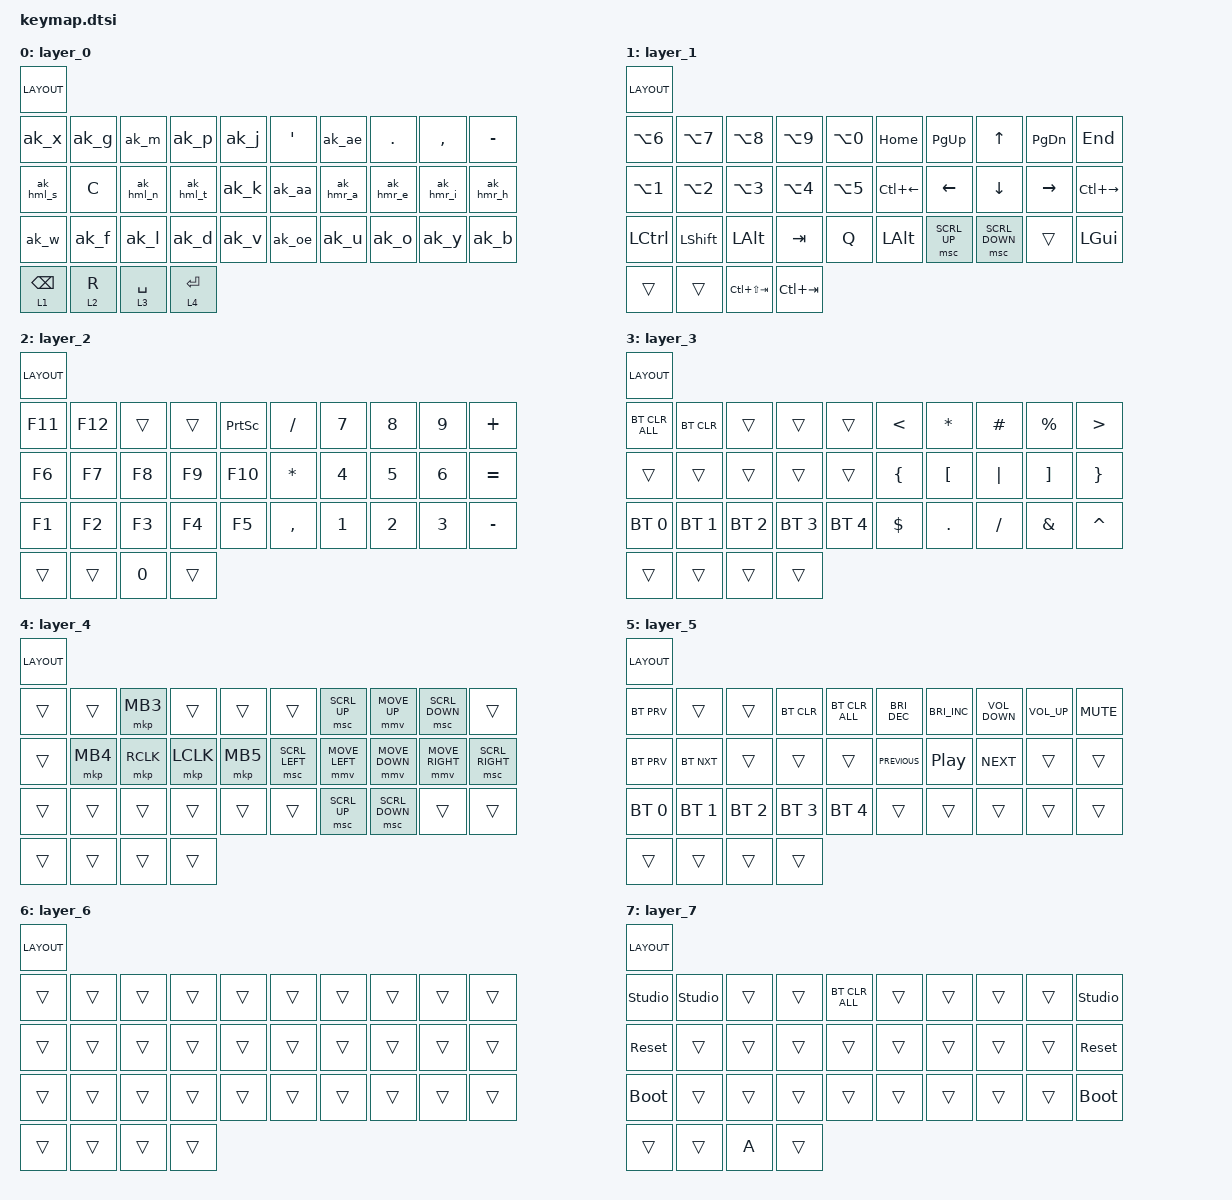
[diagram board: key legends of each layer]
// Shared by every board. The board file must define LAYOUT() and POS00..POS33
// before including this file.

#include <behaviors.dtsi>
#include <dt-bindings/zmk/bt.h>
#include <dt-bindings/zmk/keys.h>
#include <dt-bindings/zmk/pointing.h>

// Using Urob's timeless homerow mods
// Trying to make sure that sticky shift only shifts one key after being pressed.

&sk {
    release-after-ms = <1000>;
    quick-release;
};

// Faster mouse movements

#define ZMK_POINTING_DEFAULT_MOVE_VAL 1500  // default: 600
#define ZMK_POINTING_DEFAULT_SCRL_VAL 20    // default: 10

/ {
    behaviors {
        hml: home_row_mod_left {
            compatible = "zmk,behavior-hold-tap";
            #binding-cells = <2>;
            flavor = "balanced";
            require-prior-idle-ms = <150>;
            tapping-term-ms = <280>;
            quick-tap-ms = <175>;
            bindings = <&kp>, <&kp>;

            hold-trigger-key-positions = <POS00 POS01 POS02 POS03 POS04 POS10 POS11 POS12 POS13 POS14 POS20 POS21 POS22 POS23 POS24 POS30 POS31>; // List of keys on the right side of the keyboard
            hold-trigger-on-release;
        };

        hmr: home_row_mod_right {
            compatible = "zmk,behavior-hold-tap";
            #binding-cells = <2>;
            flavor = "balanced";
            require-prior-idle-ms = <150>;
            tapping-term-ms = <280>;
            quick-tap-ms = <175>;
            bindings = <&kp>, <&kp>;

            hold-trigger-key-positions = <POS05 POS06 POS07 POS08 POS09 POS15 POS16 POS17 POS18 POS19 POS25 POS26 POS27 POS28 POS29 POS32 POS33>; // List of keys on the left side of the keyboard
            hold-trigger-on-release;
        };

        // Comma Magic for homerow-mod S: tap after comma = capital S, hold = mod (unaffected)

        ak_hml_s: ak_hml_s {
            compatible = "zmk,behavior-adaptive-key";
            #binding-cells = <0>;
            bindings = <&hml LEFT_GUI S>;

            akt_comma_s {
                trigger-keys = <COMMA>;
                bindings = <&comma_cap_s>;
                max-prior-idle-ms = <500>;
            };
        };

        ak_hml_c: ak_hml_c {
            compatible = "zmk,behavior-adaptive-key";
            #binding-cells = <0>;
            bindings = <&hml LALT C>;

            akt_comma_c {
                trigger-keys = <COMMA>;
                bindings = <&comma_cap_c>;
                max-prior-idle-ms = <500>;
            };
        };

        ak_hml_n: ak_hml_n {
            compatible = "zmk,behavior-adaptive-key";
            #binding-cells = <0>;
            bindings = <&hml LEFT_SHIFT N>;

            akt_comma_n {
                trigger-keys = <COMMA>;
                bindings = <&comma_cap_n>;
                max-prior-idle-ms = <500>;
            };
        };

        ak_hml_t: ak_hml_t {
            compatible = "zmk,behavior-adaptive-key";
            #binding-cells = <0>;
            bindings = <&hml LEFT_CONTROL T>;

            akt_comma_t {
                trigger-keys = <COMMA>;
                bindings = <&comma_cap_t>;
                max-prior-idle-ms = <500>;
            };
        };

        // Comma Magic for homerow-mod A

        ak_hmr_a: ak_hmr_a {
            compatible = "zmk,behavior-adaptive-key";
            #binding-cells = <0>;
            bindings = <&hmr LEFT_CONTROL A>;

            akt_comma_a2 {
                trigger-keys = <COMMA>;
                bindings = <&comma_cap_a>;
                max-prior-idle-ms = <500>;
            };
        };

        ak_hmr_e: ak_hmr_e {
            compatible = "zmk,behavior-adaptive-key";
            #binding-cells = <0>;
            bindings = <&hmr RIGHT_SHIFT E>;

            akt_comma_e {
                trigger-keys = <COMMA>;
                bindings = <&comma_cap_e>;
                max-prior-idle-ms = <500>;
            };
        };

        ak_hmr_i: ak_hmr_i {
            compatible = "zmk,behavior-adaptive-key";
            #binding-cells = <0>;
            bindings = <&hmr LALT I>;

            akt_comma_i {
                trigger-keys = <COMMA>;
                bindings = <&comma_cap_i>;
                max-prior-idle-ms = <500>;
            };
        };

        ak_hmr_h: ak_hmr_h {
            compatible = "zmk,behavior-adaptive-key";
            #binding-cells = <0>;
            bindings = <&hmr LEFT_GUI H>;

            akt_comma_h {
                trigger-keys = <COMMA>;
                bindings = <&comma_cap_h>;
                max-prior-idle-ms = <500>;
            };
        };

        // // Trying to implement a sticky shift on tap, layer 1 on hold thing here.
        //
        // lt_sk: layer_tap_sticky_shift {
        //     compatible = "zmk,behavior-hold-tap";
        //     #binding-cells = <2>;
        //     flavor = "tap-preferred";
        //     tapping-term-ms = <150>;
        //     require-prior-idle-ms = <150>;
        //     bindings = <&mo>, <&sk>;
        // };
        // Layer-tap for R: hold = layer (param), tap = comma-aware R

        lt_r: layer_tap_r {
            compatible = "zmk,behavior-hold-tap";
            #binding-cells = <2>;
            flavor = "balanced";
            tapping-term-ms = <150>;
            require-prior-idle-ms = <150>;
            bindings = <&mo>, <&ak_r>;
        };

        // Comma Magic test: typing comma then G capitalizes it (deletes the comma)

        ak_g: ak_g {
            compatible = "zmk,behavior-adaptive-key";
            #binding-cells = <0>;
            bindings = <&kp G>;

            akt_comma_g {
                trigger-keys = <COMMA>;
                bindings = <&kp BSPC &kp LS(G)>;
                max-prior-idle-ms = <500>;
            };
        };

        ak_x: ak_x {
            compatible = "zmk,behavior-adaptive-key";
            #binding-cells = <0>;
            bindings = <&kp X>;

            akt_comma_x {
                trigger-keys = <COMMA>;
                bindings = <&kp BSPC &kp LS(X)>;
                max-prior-idle-ms = <500>;
            };
        };

        ak_q: ak_q {
            compatible = "zmk,behavior-adaptive-key";
            #binding-cells = <0>;
            bindings = <&kp Q>;

            akt_comma_q {
                trigger-keys = <COMMA>;
                bindings = <&kp BSPC &kp LS(Q)>;
                max-prior-idle-ms = <500>;
            };
        };

        ak_r: ak_r {
            compatible = "zmk,behavior-adaptive-key";
            #binding-cells = <0>;
            bindings = <&kp R>;

            akt_comma_r {
                trigger-keys = <COMMA>;
                bindings = <&kp BSPC &kp LS(R)>;
                max-prior-idle-ms = <500>;
            };
        };

        ak_m: ak_m {
            compatible = "zmk,behavior-adaptive-key";
            #binding-cells = <0>;
            bindings = <&kp M>;

            akt_comma_m {
                trigger-keys = <COMMA>;
                bindings = <&kp BSPC &kp LS(M)>;
                max-prior-idle-ms = <500>;
            };
        };

        ak_p: ak_p {
            compatible = "zmk,behavior-adaptive-key";
            #binding-cells = <0>;
            bindings = <&kp P>;

            akt_comma_p {
                trigger-keys = <COMMA>;
                bindings = <&kp BSPC &kp LS(P)>;
                max-prior-idle-ms = <500>;
            };
        };

        ak_j: ak_j {
            compatible = "zmk,behavior-adaptive-key";
            #binding-cells = <0>;
            bindings = <&kp J>;

            akt_comma_j {
                trigger-keys = <COMMA>;
                bindings = <&kp BSPC &kp LS(J)>;
                max-prior-idle-ms = <500>;
            };
        };

        ak_w: ak_w {
            compatible = "zmk,behavior-adaptive-key";
            #binding-cells = <0>;
            bindings = <&kp W>;

            akt_comma_w {
                trigger-keys = <COMMA>;
                bindings = <&kp BSPC &kp LS(W)>;
                max-prior-idle-ms = <500>;
            };
        };

        ak_f: ak_f {
            compatible = "zmk,behavior-adaptive-key";
            #binding-cells = <0>;
            bindings = <&kp F>;

            akt_comma_f {
                trigger-keys = <COMMA>;
                bindings = <&kp BSPC &kp LS(F)>;
                max-prior-idle-ms = <500>;
            };
        };

        ak_l: ak_l {
            compatible = "zmk,behavior-adaptive-key";
            #binding-cells = <0>;
            bindings = <&kp L>;

            akt_comma_l {
                trigger-keys = <COMMA>;
                bindings = <&kp BSPC &kp LS(L)>;
                max-prior-idle-ms = <500>;
            };
        };

        ak_d: ak_d {
            compatible = "zmk,behavior-adaptive-key";
            #binding-cells = <0>;
            bindings = <&kp D>;

            akt_comma_d {
                trigger-keys = <COMMA>;
                bindings = <&kp BSPC &kp LS(D)>;
                max-prior-idle-ms = <500>;
            };
        };

        ak_v: ak_v {
            compatible = "zmk,behavior-adaptive-key";
            #binding-cells = <0>;
            bindings = <&kp V>;

            akt_comma_v {
                trigger-keys = <COMMA>;
                bindings = <&kp BSPC &kp LS(V)>;
                max-prior-idle-ms = <500>;
            };
        };

        ak_u: ak_u {
            compatible = "zmk,behavior-adaptive-key";
            #binding-cells = <0>;
            bindings = <&kp U>;

            akt_comma_u {
                trigger-keys = <COMMA>;
                bindings = <&kp BSPC &kp LS(U)>;
                max-prior-idle-ms = <500>;
            };
        };

        ak_o: ak_o {
            compatible = "zmk,behavior-adaptive-key";
            #binding-cells = <0>;
            bindings = <&kp O>;

            akt_comma_o {
                trigger-keys = <COMMA>;
                bindings = <&kp BSPC &kp LS(O)>;
                max-prior-idle-ms = <500>;
            };
        };

        ak_y: ak_y {
            compatible = "zmk,behavior-adaptive-key";
            #binding-cells = <0>;
            bindings = <&kp Y>;

            akt_comma_y {
                trigger-keys = <COMMA>;
                bindings = <&kp BSPC &kp LS(Y)>;
                max-prior-idle-ms = <500>;
            };
        };

        ak_b: ak_b {
            compatible = "zmk,behavior-adaptive-key";
            #binding-cells = <0>;
            bindings = <&kp B>;

            akt_comma_b {
                trigger-keys = <COMMA>;
                bindings = <&kp BSPC &kp LS(B)>;
                max-prior-idle-ms = <500>;
            };
        };

        ak_k: ak_k {
            compatible = "zmk,behavior-adaptive-key";
            #binding-cells = <0>;
            bindings = <&kp K>;

            akt_comma_k {
                trigger-keys = <COMMA>;
                bindings = <&kp BSPC &kp LS(K)>;
                max-prior-idle-ms = <500>;
            };
        };

        // Comma Magic for umlaut macros: comma + umlaut produces the capitalized umlaut

        ak_ae: ak_ae {
            compatible = "zmk,behavior-adaptive-key";
            #binding-cells = <0>;
            bindings = <&ae_umlaut>;

            akt_comma_ae {
                trigger-keys = <COMMA>;
                bindings = <&kp BSPC &kp RA(LS(A))>;
                max-prior-idle-ms = <500>;
            };
        };

        ak_aa: ak_aa {
            compatible = "zmk,behavior-adaptive-key";
            #binding-cells = <0>;
            bindings = <&aa_umlaut>;

            akt_comma_aa {
                trigger-keys = <COMMA>;
                bindings = <&kp BSPC &kp RA(LS(W))>;
                max-prior-idle-ms = <500>;
            };
        };

        ak_oe: ak_oe {
            compatible = "zmk,behavior-adaptive-key";
            #binding-cells = <0>;
            bindings = <&oe_umlaut>;

            akt_comma_oe {
                trigger-keys = <COMMA>;
                bindings = <&kp BSPC &kp RA(LS(O))>;
                max-prior-idle-ms = <500>;
            };
        };
    };

    // Maybe add require-idle-ms 150 for horizontal combos and change timeout-ms to 30 for vertical and idle to 50 as per urob

    combos {
        compatible = "zmk,combos";

        //    timeout-ms = <20>;

        m_enter {
            bindings = <&kp ENTER>;
            key-positions = <POS16 POS17 POS18>;
            timeout-ms = <20>;
            require-prior-idle-ms = <150>;
        };

        th {
            bindings = <&th>;
            key-positions = <POS12 POS13>;
            timeout-ms = <20>;
        };

        left_par {
            bindings = <&kp LEFT_PARENTHESIS>;
            key-positions = <POS16 POS17>;
            timeout-ms = <20>;
            require-prior-idle-ms = <150>;
        };

        right_par {
            bindings = <&kp RIGHT_PARENTHESIS>;
            key-positions = <POS17 POS18>;
            timeout-ms = <20>;
            require-prior-idle-ms = <150>;
        };

        // equals {
        //     bindings = <&kp EQUAL>;
        //     key-positions = <POS18 POS19>;
        //     timeout-ms = <20>;
        // };

        colon {
            bindings = <&kp COLON>;
            key-positions = <POS16 POS18>;
            timeout-ms = <20>;
            require-prior-idle-ms = <150>;
        };

        curvy {
            bindings = <&kp TILDE>;
            key-positions = <POS25 POS29>;
            timeout-ms = <20>;
            require-prior-idle-ms = <150>;
        };

        underscore {
            bindings = <&kp UNDER>;
            key-positions = <POS28 POS26>;
            timeout-ms = <20>;
            require-prior-idle-ms = <150>;
        };

        snabela {
            bindings = <&kp AT>;
            key-positions = <POS05 POS06>;
            timeout-ms = <20>;
            require-prior-idle-ms = <150>;
        };

        tab {
            bindings = <&kp TAB>;
            key-positions = <POS00 POS01>;
            timeout-ms = <20>;
            require-prior-idle-ms = <150>;
        };

        Stab {
            bindings = <&kp LS(TAB)>;
            key-positions = <POS00 POS01 POS02>;
            timeout-ms = <20>;
            require-prior-idle-ms = <150>;
        };

        space {
            bindings = <&kp SPACE>;
            key-positions = <POS13 POS14>;
            timeout-ms = <20>;
            require-prior-idle-ms = <150>;
        };

        escape {
            bindings = <&kp ESCAPE>;
            key-positions = <POS10 POS13>;
            timeout-ms = <20>;
            require-prior-idle-ms = <150>;
        };

        zed {
            bindings = <&kp Z>;
            key-positions = <POS11 POS13>;
            timeout-ms = <20>;
            require-prior-idle-ms = <150>;
        };

        excl {
            bindings = <&kp EXCLAMATION>;
            key-positions = <POS06 POS07>;
            timeout-ms = <20>;
        };

        doubleq {
            bindings = <&kp DOUBLE_QUOTES>;
            key-positions = <POS06 POS08>;
            timeout-ms = <20>;
        };

        question {
            bindings = <&kp QUESTION>;
            key-positions = <POS07 POS08>;
            timeout-ms = <20>;
        };

        Backspace {
            bindings = <&kp BACKSPACE>;
            key-positions = <POS15 POS16>;
            timeout-ms = <20>;
        };

        ion {
            bindings = <&ion>;
            key-positions = <POS06 POS07 POS08>;
            timeout-ms = <20>;
        };

        ing {
            bindings = <&ing>;
            key-positions = <POS26 POS27 POS28>;
            timeout-ms = <20>;
        };

        gh {
            bindings = <&gh>;
            key-positions = <POS01 POS02>;
            timeout-ms = <20>;
        };

        wh {
            bindings = <&wh>;
            key-positions = <POS20 POS21>;
            timeout-ms = <20>;
        };

        sh {
            bindings = <&sh>;
            key-positions = <POS10 POS11>;
            timeout-ms = <20>;
        };

        ch {
            bindings = <&ch>;
            key-positions = <POS11 POS12>;
            timeout-ms = <20>;
        };

        ph {
            bindings = <&ph>;
            key-positions = <POS21 POS23>;
            timeout-ms = <20>;
        };

        copy {
            bindings = <&kp LC(C)>;
            key-positions = <POS21 POS22>;
            timeout-ms = <20>;
            require-prior-idle-ms = <150>;
        };

        paste {
            bindings = <&kp LC(V)>;
            key-positions = <POS22 POS23>;
            timeout-ms = <20>;
            require-prior-idle-ms = <150>;
        };

        sall {
            bindings = <&kp LC(A)>;
            key-positions = <POS20 POS23>;
            timeout-ms = <20>;
            require-prior-idle-ms = <150>;
        };

        undo {
            bindings = <&kp LC(Z)>;
            key-positions = <POS20 POS21 POS22>;
            timeout-ms = <20>;
            require-prior-idle-ms = <150>;
        };

        redo {
            bindings = <&kp LC(LS(Z))>;
            key-positions = <POS20 POS21 POS22 POS23>;
            timeout-ms = <20>;
            require-prior-idle-ms = <150>;
        };

        quit {
            bindings = <&kp LC(Q)>;
            key-positions = <POS04 POS14>;
            timeout-ms = <30>;
            require-prior-idle-ms = <50>;
        };

        new {
            bindings = <&kp LC(N)>;
            key-positions = <POS14 POS24>;
            timeout-ms = <20>;
            require-prior-idle-ms = <150>;
        };

        close {
            bindings = <&kp LC(W)>;
            key-positions = <POS05 POS15>;
            timeout-ms = <30>;
            require-prior-idle-ms = <50>;
        };

        open {
            bindings = <&kp LC(O)>;
            key-positions = <POS05 POS25>;
            timeout-ms = <20>;
            require-prior-idle-ms = <150>;
        };

        selword {
            bindings = <&selword>;
            key-positions = <POS20 POS24>;
            timeout-ms = <20>;
            require-prior-idle-ms = <150>;
        };

        findsel {
            bindings = <&findsel>;
            key-positions = <POS10 POS14>;
            timeout-ms = <20>;
            require-prior-idle-ms = <150>;
        };

        slash {
            bindings = <&kp SLASH>;
            key-positions = <POS01 POS02 POS03>;
            timeout-ms = <20>;
        };

        altslash {
            bindings = <&kp SLASH>;
            key-positions = <POS17 POS27>;
            timeout-ms = <30>;
            require-prior-idle-ms = <50>;
        };

        pipe {
            bindings = <&kp PIPE>;
            key-positions = <POS18 POS28>;
            timeout-ms = <30>;
            require-prior-idle-ms = <50>;
        };

        plus {
            bindings = <&kp PLUS>;
            key-positions = <POS06 POS16>;
            timeout-ms = <30>;
            require-prior-idle-ms = <50>;
        };

        minus {
            bindings = <&kp MINUS>;
            key-positions = <POS16 POS26>;
            timeout-ms = <30>;
            require-prior-idle-ms = <50>;
        };

        asterix {
            bindings = <&kp ASTRK>;
            key-positions = <POS07 POS17>;
            timeout-ms = <30>;
            require-prior-idle-ms = <50>;
        };

        andthen {
            bindings = <&kp AMPS>;
            key-positions = <POS08 POS18>;
            timeout-ms = <30>;
            require-prior-idle-ms = <50>;
        };

        lbracket {
            bindings = <&kp LEFT_BRACKET>;
            key-positions = <POS26 POS27>;
            timeout-ms = <20>;
            require-prior-idle-ms = <150>;
        };

        rbracket {
            bindings = <&kp RIGHT_BRACKET>;
            key-positions = <POS27 POS28>;
            timeout-ms = <20>;
            require-prior-idle-ms = <150>;
        };

        q {
            bindings = <&ak_q>;
            key-positions = <POS09 POS19>;
            timeout-ms = <30>;
            require-prior-idle-ms = <50>;
        };

        del {
            bindings = <&kp DELETE>;
            key-positions = <POS08 POS09>;
            timeout-ms = <20>;
            require-prior-idle-ms = <150>;
        };

        hash {
            bindings = <&kp HASH>;
            key-positions = <POS02 POS12>;
            timeout-ms = <30>;
            require-prior-idle-ms = <50>;
        };

        dollar {
            bindings = <&kp DOLLAR>;
            key-positions = <POS03 POS13>;
            timeout-ms = <30>;
            require-prior-idle-ms = <50>;
        };

        equality {
            bindings = <&kp EQUAL>;
            key-positions = <POS13 POS23>;
            timeout-ms = <30>;
            require-prior-idle-ms = <50>;
        };

        porciento {
            bindings = <&kp PERCENT>;
            key-positions = <POS00 POS10>;
            timeout-ms = <30>;
            require-prior-idle-ms = <50>;
        };

        grave {
            bindings = <&kp GRAVE>;
            key-positions = <POS10 POS20>;
            timeout-ms = <30>;
            require-prior-idle-ms = <50>;
        };

        backslash {
            bindings = <&kp BACKSLASH>;
            key-positions = <POS12 POS22>;
            timeout-ms = <30>;
            require-prior-idle-ms = <50>;
        };

        hd_enter {
            bindings = <&kp ENTER>;
            key-positions = <POS23 POS24>;
            timeout-ms = <20>;
            require-prior-idle-ms = <150>;
        };

        que {
            bindings = <&qu>;
            key-positions = <POS01 POS03>;
            timeout-ms = <20>;
        };

        sch {
            bindings = <&sch>;
            key-positions = <POS10 POS11 POS12>;
            timeout-ms = <20>;
        };

        tch {
            bindings = <&tch>;
            key-positions = <POS10 POS11 POS13>;
            timeout-ms = <20>;
        };

        Ill {
            bindings = <&Ill>;
            key-positions = <POS18 POS22>;
            timeout-ms = <30>;
        };

        Ive {
            bindings = <&Ive>;
            key-positions = <POS18 POS24>;
            timeout-ms = <30>;
        };

        Id {
            bindings = <&Id>;
            key-positions = <POS18 POS23>;
            timeout-ms = <30>;
        };

        Im {
            bindings = <&Im>;
            key-positions = <POS02 POS18>;
            timeout-ms = <30>;
        };

        Ime {
            bindings = <&kp LS(I)>;
            key-positions = <POS18 POS19>;
            timeout-ms = <20>;
            require-prior-idle-ms = <150>;
        };

        youll {
            bindings = <&youll>;
            key-positions = <POS22 POS28>;
            timeout-ms = <30>;
        };

        youve {
            bindings = <&youve>;
            key-positions = <POS24 POS28>;
            timeout-ms = <30>;
        };

        youd {
            bindings = <&youd>;
            key-positions = <POS23 POS28>;
            timeout-ms = <30>;
        };

        your {
            bindings = <&your>;
            key-positions = <POS28 POS30>;
            timeout-ms = <30>;
        };
    };

    // Maybe add timing to digraph macros - tap-ms = 10 (is the value that HD creator uses.)

    macros {
        comma_cap_s: comma_cap_s {
            compatible = "zmk,behavior-macro";
            #binding-cells = <0>;
            bindings = <&kp BSPC &kp LS(S)>;
            label = "COMMA_CAP_S";
        };

        comma_cap_c: comma_cap_c {
            compatible = "zmk,behavior-macro";
            #binding-cells = <0>;
            bindings = <&kp BSPC &kp LS(C)>;
            label = "COMMA_CAP_C";
        };

        comma_cap_n: comma_cap_n {
            compatible = "zmk,behavior-macro";
            #binding-cells = <0>;
            bindings = <&kp BSPC &kp LS(N)>;
            label = "COMMA_CAP_N";
        };

        comma_cap_t: comma_cap_t {
            compatible = "zmk,behavior-macro";
            #binding-cells = <0>;
            bindings = <&kp BSPC &kp LS(T)>;
            label = "COMMA_CAP_T";
        };

        comma_cap_a: comma_cap_a {
            compatible = "zmk,behavior-macro";
            #binding-cells = <0>;
            bindings = <&kp BSPC &kp LS(A)>;
            label = "COMMA_CAP_A";
        };

        comma_cap_e: comma_cap_e {
            compatible = "zmk,behavior-macro";
            #binding-cells = <0>;
            bindings = <&kp BSPC &kp LS(E)>;
            label = "COMMA_CAP_E";
        };

        comma_cap_i: comma_cap_i {
            compatible = "zmk,behavior-macro";
            #binding-cells = <0>;
            bindings = <&kp BSPC &kp LS(I)>;
            label = "COMMA_CAP_I";
        };

        comma_cap_h: comma_cap_h {
            compatible = "zmk,behavior-macro";
            #binding-cells = <0>;
            bindings = <&kp BSPC &kp LS(H)>;
            label = "COMMA_CAP_H";
        };

        ae_umlaut: ae_umlaut {
            compatible = "zmk,behavior-macro";
            #binding-cells = <0>;
            bindings = <&kp RA(A)>;
            label = "AE_UMLAUT";
        };

        aa_umlaut: aa_umlaut {
            compatible = "zmk,behavior-macro";
            #binding-cells = <0>;
            bindings = <&kp RA(W)>;
            label = "AA_UMLAUT";
        };

        oe_umlaut: oe_umlaut {
            compatible = "zmk,behavior-macro";
            #binding-cells = <0>;
            bindings = <&kp RA(O)>;
            label = "OE_UMLAUT";
        };

        // Plain adaptive-key for T (no mod), used only as the first step inside digraph macros

        ak_t: ak_t {
            compatible = "zmk,behavior-adaptive-key";
            #binding-cells = <0>;
            bindings = <&kp T>;

            akt_t_comma {
                trigger-keys = <COMMA>;
                bindings = <&kp BSPC &kp LS(T)>;
                max-prior-idle-ms = <500>;
                strict-modifiers;
            };
        };

        ak_c: ak_c {
            compatible = "zmk,behavior-adaptive-key";
            #binding-cells = <0>;
            bindings = <&kp C>;

            akt_c_comma {
                trigger-keys = <COMMA>;
                bindings = <&kp BSPC &kp LS(C)>;
                max-prior-idle-ms = <500>;
                strict-modifiers;
            };
        };

        ak_s: ak_s {
            compatible = "zmk,behavior-adaptive-key";
            #binding-cells = <0>;
            bindings = <&kp S>;

            akt_s_comma {
                trigger-keys = <COMMA>;
                bindings = <&kp BSPC &kp LS(S)>;
                max-prior-idle-ms = <500>;
                strict-modifiers;
            };
        };

        ak_i: ak_i {
            compatible = "zmk,behavior-adaptive-key";
            #binding-cells = <0>;
            bindings = <&kp I>;

            akt_i_comma {
                trigger-keys = <COMMA>;
                bindings = <&kp BSPC &kp LS(I)>;
                max-prior-idle-ms = <500>;
                strict-modifiers;
            };
        };

        ak_g2: ak_g2 {
            compatible = "zmk,behavior-adaptive-key";
            #binding-cells = <0>;
            bindings = <&kp G>;

            akt_g2_comma {
                trigger-keys = <COMMA>;
                bindings = <&kp BSPC &kp LS(G)>;
                max-prior-idle-ms = <500>;
                strict-modifiers;
            };
        };

        ak_p2: ak_p2 {
            compatible = "zmk,behavior-adaptive-key";
            #binding-cells = <0>;
            bindings = <&kp P>;

            akt_p2_comma {
                trigger-keys = <COMMA>;
                bindings = <&kp BSPC &kp LS(P)>;
                max-prior-idle-ms = <500>;
                strict-modifiers;
            };
        };

        th: th {
            compatible = "zmk,behavior-macro";
            #binding-cells = <0>;
            tap-ms = <10>;
            bindings =
                <&ak_t>,
                <&macro_release>,
                <&kp LSHFT>,
                <&macro_release>,
                <&kp RSHFT>,
                <&macro_tap>,
                <&kp H>;

            label = "TH";
        };

        ch: ch {
            compatible = "zmk,behavior-macro";
            #binding-cells = <0>;
            tap-ms = <10>;
            bindings =
                <&ak_c>,
                <&macro_release>,
                <&kp LSHFT>,
                <&macro_release>,
                <&kp RSHFT>,
                <&macro_tap>,
                <&kp H>;

            label = "CH";
        };

        sch: sch {
            compatible = "zmk,behavior-macro";
            #binding-cells = <0>;
            tap-ms = <10>;
            bindings =
                <&ak_s>,
                <&macro_release>,
                <&kp LSHFT>,
                <&macro_release>,
                <&kp RSHFT>,
                <&macro_tap>,
                <&kp C &kp H>;

            label = "SCH";
        };

        tch: tch {
            compatible = "zmk,behavior-macro";
            #binding-cells = <0>;
            tap-ms = <10>;
            bindings =
                <&ak_t>,
                <&macro_release>,
                <&kp LSHFT>,
                <&macro_release>,
                <&kp RSHFT>,
                <&macro_tap>,
                <&kp C &kp H>;

            label = "TCH";
        };

        qu: qu {
            compatible = "zmk,behavior-macro";
            #binding-cells = <0>;
            tap-ms = <10>;
            bindings =
                <&kp Q>,
                <&macro_release>,
                <&kp LSHFT>,
                <&macro_release>,
                <&kp RSHFT>,
                <&macro_tap>,
                <&kp U>;

            label = "QU";
        };

        wh: wh {
            compatible = "zmk,behavior-macro";
            #binding-cells = <0>;
            tap-ms = <10>;
            bindings =
                <&ak_w>,
                <&macro_release>,
                <&kp LSHFT>,
                <&macro_release>,
                <&kp RSHFT>,
                <&macro_tap>,
                <&kp H>;

            label = "WH";
        };

        sh: sh {
            compatible = "zmk,behavior-macro";
            #binding-cells = <0>;
            tap-ms = <10>;
            bindings =
                <&ak_s>,
                <&macro_release>,
                <&kp LSHFT>,
                <&macro_release>,
                <&kp RSHFT>,
                <&macro_tap>,
                <&kp H>;

            label = "SH";
        };

        ing: ing {
            compatible = "zmk,behavior-macro";
            #binding-cells = <0>;
            tap-ms = <10>;
            bindings =
                <&kp I>,
                <&macro_release>,
                <&kp LSHFT>,
                <&macro_release>,
                <&kp RSHFT>,
                <&macro_tap>,
                <&kp N &kp G>;

            label = "ING";
        };

        ion: ion {
            compatible = "zmk,behavior-macro";
            #binding-cells = <0>;
            tap-ms = <10>;
            bindings = <&kp I &kp O &kp N>;
            label = "ION";
        };

        gh: gh {
            compatible = "zmk,behavior-macro";
            #binding-cells = <0>;
            tap-ms = <10>;
            bindings =
                <&ak_g2>,
                <&macro_release>,
                <&kp LSHFT>,
                <&macro_release>,
                <&kp RSHFT>,
                <&macro_tap>,
                <&kp H>;

            label = "GH";
        };

        ph: ph {
            compatible = "zmk,behavior-macro";
            #binding-cells = <0>;
            tap-ms = <10>;
            bindings =
                <&ak_p2>,
                <&macro_release>,
                <&kp LSHFT>,
                <&macro_release>,
                <&kp RSHFT>,
                <&macro_tap>,
                <&kp H>;

            label = "PH";
        };

        findsel: findsel {
            compatible = "zmk,behavior-macro";
            #binding-cells = <0>;
            bindings =
                <&macro_tap>,
                <&kp LC(C)>,
                <&macro_tap>,
                <&kp LC(F)>,
                <&macro_tap>,
                <&kp LC(V)>,
                <&macro_tap>,
                <&kp RETURN>,
                <&macro_tap>,
                <&kp LC(G)>;

            label = "FINDSEL";
        };

        selword: selword {
            compatible = "zmk,behavior-macro";
            #binding-cells = <0>;
            bindings =
                <&macro_tap>,
                <&kp LC(LEFT)>,
                <&macro_tap>,
                <&kp LS(LC(RIGHT))>;

            label = "SELWORD";
        };

        your: your {
            compatible = "zmk,behavior-macro";
            #binding-cells = <0>;
            bindings =
                <&kp Y>,
                <&macro_release>,
                <&kp LSHFT>,
                <&macro_release>,
                <&kp RSHFT>,
                <&macro_tap>,
                <&kp O &kp U &kp R>;

            label = "YOUR";
        };

        Ill: Ill {
            compatible = "zmk,behavior-macro";
            #binding-cells = <0>;
            bindings = <&kp LS(I) &kp SQT &kp L &kp L &kp SPACE>;
            label = "ILL";
        };

        Id: Id {
            compatible = "zmk,behavior-macro";
            #binding-cells = <0>;
            bindings = <&kp LS(I) &kp SQT &kp D &kp SPACE>;
            label = "ID";
        };

        Im: Im {
            compatible = "zmk,behavior-macro";
            #binding-cells = <0>;
            bindings = <&kp LS(I) &kp SQT &kp M &kp SPACE>;
            label = "IM";
        };

        Ive: Ive {
            compatible = "zmk,behavior-macro";
            #binding-cells = <0>;
            bindings = <&kp LS(I) &kp SQT &kp V &kp E &kp SPACE>;
            label = "IVE";
        };

        youve: youve {
            compatible = "zmk,behavior-macro";
            #binding-cells = <0>;
            bindings =
                <&kp Y>,
                <&macro_release>,
                <&kp LSHFT>,
                <&macro_release>,
                <&kp RSHFT>,
                <&macro_tap>,
                <&kp O &kp U &kp APOSTROPHE &kp V &kp E &kp SPACE>;

            label = "YOUVE";
        };

        youre: youre {
            compatible = "zmk,behavior-macro";
            #binding-cells = <0>;
            bindings =
                <&kp Y>,
                <&macro_release>,
                <&kp LSHFT>,
                <&macro_release>,
                <&kp RSHFT>,
                <&macro_tap>,
                <&kp O &kp U &kp APOSTROPHE &kp R &kp E &kp SPACE>;

            label = "YOURE";
        };

        youd: youd {
            compatible = "zmk,behavior-macro";
            #binding-cells = <0>;
            bindings =
                <&kp Y>,
                <&macro_release>,
                <&kp LSHFT>,
                <&macro_release>,
                <&kp RSHFT>,
                <&macro_tap>,
                <&kp O &kp U &kp APOSTROPHE &kp D &kp SPACE>;

            label = "YOUD";
        };

        youll: youll {
            compatible = "zmk,behavior-macro";
            #binding-cells = <0>;
            bindings =
                <&kp Y>,
                <&macro_release>,
                <&kp LSHFT>,
                <&macro_release>,
                <&kp RSHFT>,
                <&macro_tap>,
                <&kp O &kp U &kp APOSTROPHE &kp L &kp L &kp SPACE>;

            label = "YOULL";
        };
    };

    keymap {
        compatible = "zmk,keymap";

        layer_0 {
            bindings = <
  LAYOUT(
    &ak_x,           &ak_g,           &ak_m,           &ak_p,           &ak_j,           &kp APOS,        &ak_ae,          &kp DOT,         &kp COMMA,       &kp MINUS,
    &ak_hml_s,       &kp C,       &ak_hml_n,       &ak_hml_t,       &ak_k,           &ak_aa,          &ak_hmr_a,       &ak_hmr_e,       &ak_hmr_i,       &ak_hmr_h,
    &ak_w,           &ak_f,           &ak_l,           &ak_d,           &ak_v,           &ak_oe,          &ak_u,           &ak_o,           &ak_y,           &ak_b,
    &lt 1 BACKSPACE, &lt_r 2 R,       &lt 3 SPACE,     &lt 4 ENTER
  )
    >;
        };

        layer_1 {
            bindings = <
  LAYOUT(
    &kp LA(NUMBER_6),    &kp LA(NUMBER_7),    &kp LA(N8),          &kp LA(N9),          &kp LA(N0),          &kp HOME,            &kp PAGE_UP,         &kp UP_ARROW,        &kp PAGE_DOWN,       &kp END,
    &kp LA(NUMBER_1),    &kp LA(NUMBER_2),    &kp LA(NUMBER_3),    &kp LA(NUMBER_4),    &kp LA(NUMBER_5),    &kp LC(LEFT_ARROW),  &kp LEFT_ARROW,      &kp DOWN_ARROW,      &kp RIGHT,           &kp LC(RIGHT_ARROW),
    &kp LEFT_CONTROL,    &kp LEFT_SHIFT,      &kp LEFT_ALT,        &kp TAB,             &kp Q,               &kp LEFT_ALT,        &msc SCRL_UP,        &msc SCRL_DOWN,      &trans,              &kp LEFT_GUI,
    &trans,              &trans,              &kp LC(LS(TAB)),     &kp LC(TAB)
  )
    >;
        };

        layer_2 {
            bindings = <
  LAYOUT(
    &kp F11,         &kp F12,         &trans,          &trans,          &kp PRINTSCREEN, &kp SLASH,       &kp N7,          &kp N8,          &kp N9,          &kp PLUS,
    &kp F6,          &kp F7,          &kp F8,          &kp F9,          &kp F10,         &kp ASTRK,       &kp NUMBER_4,    &kp N5,          &kp NUMBER_6,    &kp EQUAL,
    &kp F1,          &kp F2,          &kp F3,          &kp F4,          &kp F5,          &kp COMMA,       &kp NUMBER_1,    &kp NUMBER_2,    &kp NUMBER_3,    &kp MINUS,
    &trans,          &trans,          &kp N0,          &trans
  )
    >;
        };

        layer_3 {
            bindings = <
  LAYOUT(
    &bt BT_CLR_ALL,    &bt BT_CLR,        &trans,            &trans,            &trans,            &kp LESS_THAN,     &kp ASTRK,         &kp HASH,          &kp PERCENT,       &kp GREATER_THAN,
    &trans,            &trans,            &trans,            &trans,            &trans,            &kp LEFT_BRACE,    &kp LEFT_BRACKET,  &kp PIPE,          &kp RIGHT_BRACKET, &kp RIGHT_BRACE,
    &bt BT_SEL 0,      &bt BT_SEL 1,      &bt BT_SEL 2,      &bt BT_SEL 3,      &bt BT_SEL 4,      &kp DOLLAR,        &kp DOT,           &kp SLASH,         &kp AMPS,          &kp CARET,
    &trans,            &trans,            &trans,            &trans
  )
    >;
        };

        layer_4 {
            bindings = <
  LAYOUT(
    &trans,          &trans,          &mkp MB3,        &trans,          &trans,          &trans,          &msc SCRL_UP,    &mmv MOVE_UP,    &msc SCRL_DOWN,  &trans,
    &trans,          &mkp MB4,        &mkp RCLK,       &mkp LCLK,       &mkp MB5,        &msc SCRL_LEFT,  &mmv MOVE_LEFT,  &mmv MOVE_DOWN,  &mmv MOVE_RIGHT, &msc SCRL_RIGHT,
    &trans,          &trans,          &trans,          &trans,          &trans,          &trans,          &msc SCRL_UP,    &msc SCRL_DOWN,  &trans,          &trans,
    &trans,          &trans,          &trans,          &trans
  )
    >;
        };

        layer_5 {
            bindings = <
  LAYOUT(
    &bt BT_PRV,           &trans,               &trans,               &bt BT_CLR,           &bt BT_CLR_ALL,       &kp C_BRIGHTNESS_DEC, &kp C_BRI_INC,        &kp C_VOLUME_DOWN,    &kp C_VOLUME_UP,      &kp K_MUTE,
    &bt BT_PRV,           &bt BT_NXT,           &trans,               &trans,               &trans,               &kp C_PREVIOUS,       &kp C_PLAY_PAUSE,     &kp C_NEXT,           &trans,               &trans,
    &bt BT_SEL 0,         &bt BT_SEL 1,         &bt BT_SEL 2,         &bt BT_SEL 3,         &bt BT_SEL 4,         &trans,               &trans,               &trans,               &trans,               &trans,
    &trans,               &trans,               &trans,               &trans
  )
    >;
        };

        layer_6 {
            bindings = <
  LAYOUT(
    &trans, &trans, &trans, &trans, &trans, &trans, &trans, &trans, &trans, &trans,
    &trans, &trans, &trans, &trans, &trans, &trans, &trans, &trans, &trans, &trans,
    &trans, &trans, &trans, &trans, &trans, &trans, &trans, &trans, &trans, &trans,
    &trans, &trans, &trans, &trans
  )
    >;
        };

        layer_7 {
            bindings = <
  LAYOUT(
    &studio_unlock, &studio_unlock, &trans,         &trans,         &bt BT_CLR_ALL, &trans,         &trans,         &trans,         &trans,         &studio_unlock,
    &sys_reset,     &trans,         &trans,         &trans,         &trans,         &trans,         &trans,         &trans,         &trans,         &sys_reset,
    &bootloader,    &trans,         &trans,         &trans,         &trans,         &trans,         &trans,         &trans,         &trans,         &bootloader,
    &trans,         &trans,         &kp A,          &trans
  )
    >;
        };
    };

    // Layer 1 (RIGHT) + Layer 2 (LEFT) at the same time -> Layer 7 (TRI)

    conditional_layers {
        compatible = "zmk,conditional-layers";

        tri_layer {
            if-layers = <1 2>;
            then-layer = <7>;
        };

        funf {
            if-layers = <2 4>;
            then-layer = <5>;
        };
    };
};
